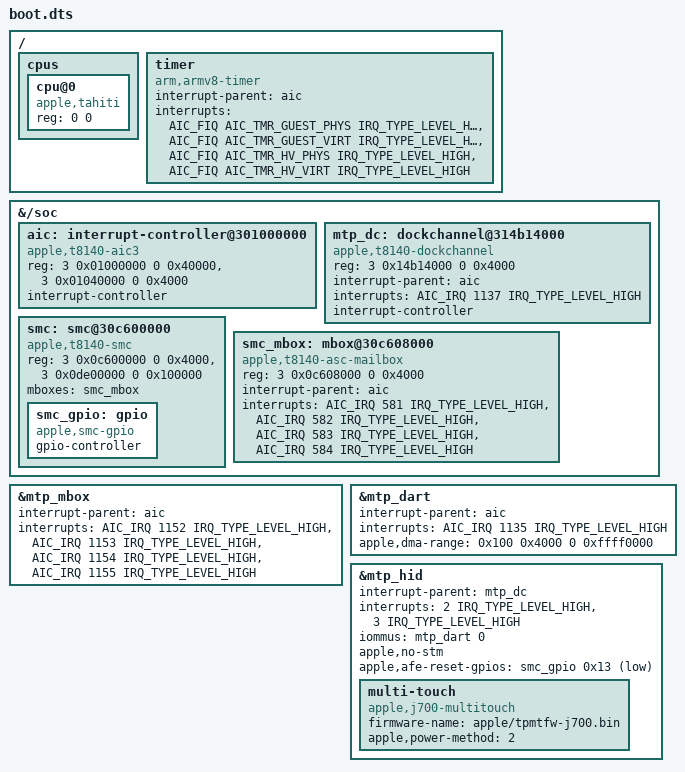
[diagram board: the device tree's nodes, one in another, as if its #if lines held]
/* SPDX-License-Identifier: GPL-2.0+ OR MIT */
/* Experimental single-CPU Linux extension to our tested U-Boot handoff. */
#include "arch/arm/dts/t8140-j700.dts"
#include <dt-bindings/interrupt-controller/apple-aic.h>
#include <dt-bindings/interrupt-controller/irq.h>
#include <dt-bindings/gpio/gpio.h>

#ifdef NEO_USB2
#include "usb2.dtsi"
#endif

/ {
    cpus {
        #address-cells = <2>;
        #size-cells = <0>;
        cpu@0 {
            compatible = "apple,tahiti";
            device_type = "cpu";
            /* Filled from MPIDR_EL1 by m1n1; not an ADT logical CPU ID. */
            reg = <0 0>;
        };
    };

    timer {
        compatible = "arm,armv8-timer";
        interrupt-parent = <&aic>;
        interrupt-names = "phys", "virt", "hyp-phys", "hyp-virt";
        interrupts = <AIC_FIQ AIC_TMR_GUEST_PHYS IRQ_TYPE_LEVEL_HIGH>,
                     <AIC_FIQ AIC_TMR_GUEST_VIRT IRQ_TYPE_LEVEL_HIGH>,
                     <AIC_FIQ AIC_TMR_HV_PHYS IRQ_TYPE_LEVEL_HIGH>,
                     <AIC_FIQ AIC_TMR_HV_VIRT IRQ_TYPE_LEVEL_HIGH>;
    };
};

&{/soc} {
    /* Captured J700 ADT: config 0x10000, iack 0x40000, stride 0x4a00;
     * cap0/max IRQ registers 4/12. Same register layout as the existing AIC3.
     */
    aic: interrupt-controller@301000000 {
        compatible = "apple,t8140-aic3", "apple,t8122-aic3";
        reg = <3 0x01000000 0 0x40000>, <3 0x01040000 0 0x4000>;
        interrupt-controller;
        #interrupt-cells = <3>;
        #address-cells = <0>;
    };

	mtp_dc: dockchannel@314b14000 {
		compatible = "apple,t8140-dockchannel", "apple,dockchannel";
		reg = <3 0x14b14000 0 0x4000>;
		reg-names = "irq";
		interrupt-parent = <&aic>;
		interrupts = <AIC_IRQ 1137 IRQ_TYPE_LEVEL_HIGH>;
		interrupt-controller;
		#interrupt-cells = <2>;
		#address-cells = <0>;
	};
};

&mtp_mbox {
	interrupt-parent = <&aic>;
	interrupts = <AIC_IRQ 1152 IRQ_TYPE_LEVEL_HIGH>,
		     <AIC_IRQ 1153 IRQ_TYPE_LEVEL_HIGH>,
		     <AIC_IRQ 1154 IRQ_TYPE_LEVEL_HIGH>,
		     <AIC_IRQ 1155 IRQ_TYPE_LEVEL_HIGH>;
	interrupt-names = "send-empty", "send-not-empty", "recv-empty", "recv-not-empty";
};

&mtp_dart {
	interrupt-parent = <&aic>;
	interrupts = <AIC_IRQ 1135 IRQ_TYPE_LEVEL_HIGH>;
	apple,dma-range = <0x100 0x4000 0 0xffff0000>;
};

&mtp_hid {
	interrupt-parent = <&mtp_dc>;
	interrupts = <2 IRQ_TYPE_LEVEL_HIGH>, <3 IRQ_TYPE_LEVEL_HIGH>;
	interrupt-names = "tx", "rx";
	iommus = <&mtp_dart 0>;
	apple,no-stm;
};

#if defined(NEO_TOUCHPAD) || defined(NEO_SMC)
&{/soc} {
	smc: smc@30c600000 {
		compatible = "apple,t8140-smc", "apple,t8103-smc";
		/* SRAM is the ADT iop-smc-nub region, not the wrapper window. */
		reg = <3 0x0c600000 0 0x4000>, <3 0x0de00000 0 0x100000>;
		reg-names = "smc", "sram";
		mboxes = <&smc_mbox>;

		smc_gpio: gpio {
			compatible = "apple,smc-gpio";
			gpio-controller;
			#gpio-cells = <2>;
		};
	};

	smc_mbox: mbox@30c608000 {
		compatible = "apple,t8140-asc-mailbox", "apple,asc-mailbox-v4";
		reg = <3 0x0c608000 0 0x4000>;
		interrupt-parent = <&aic>;
		interrupts = <AIC_IRQ 581 IRQ_TYPE_LEVEL_HIGH>,
			     <AIC_IRQ 582 IRQ_TYPE_LEVEL_HIGH>,
			     <AIC_IRQ 583 IRQ_TYPE_LEVEL_HIGH>,
			     <AIC_IRQ 584 IRQ_TYPE_LEVEL_HIGH>;
		interrupt-names = "send-empty", "send-not-empty", "recv-empty", "recv-not-empty";
		#mbox-cells = <0>;
	};
};

#endif
#ifdef NEO_TOUCHPAD
&mtp_hid {
	apple,afe-reset-gpios = <&smc_gpio 0x13 GPIO_ACTIVE_LOW>;

	multi-touch {
		compatible = "apple,j700-multitouch";
		firmware-name = "apple/tpmtfw-j700.bin";
		apple,power-method = <2>;
	};
};
#endif
